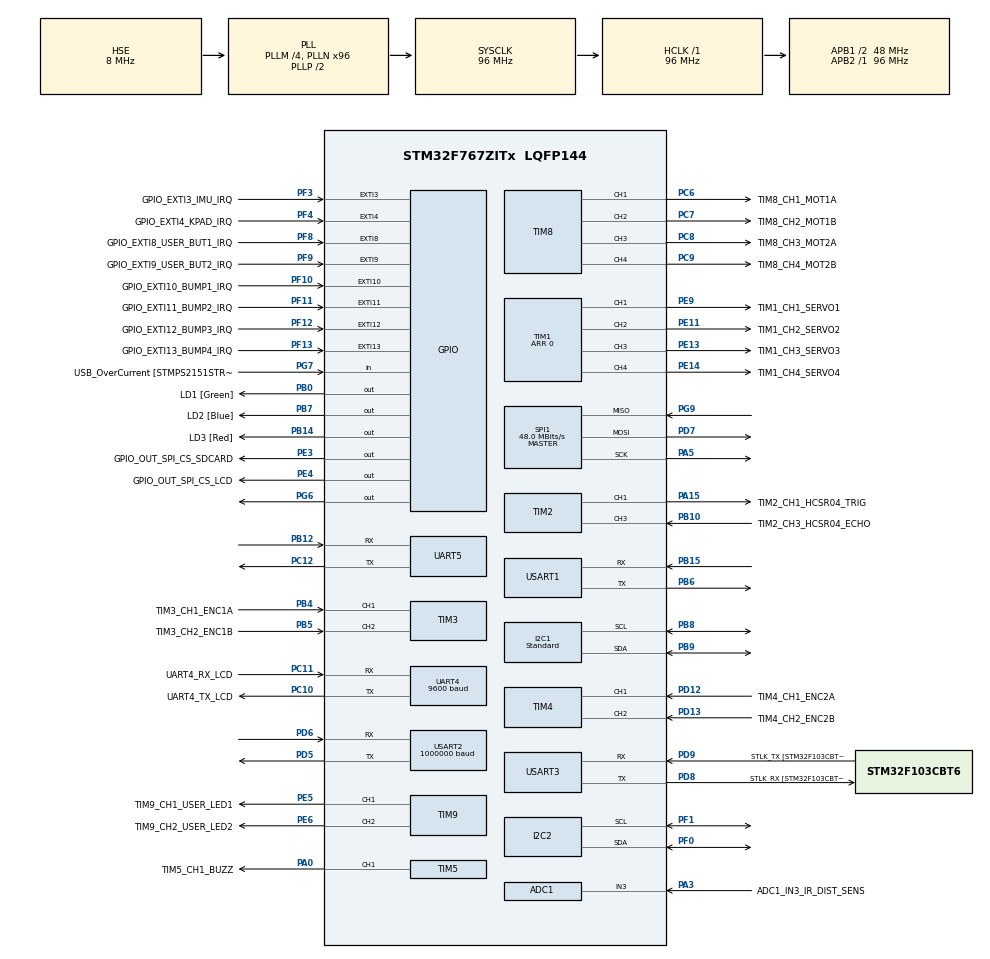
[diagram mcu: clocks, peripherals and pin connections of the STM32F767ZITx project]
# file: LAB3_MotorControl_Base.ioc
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ADC1.Channel-1\#ChannelRegularConversion=ADC_CHANNEL_3
ADC1.NbrOfConversionFlag=1
ADC1.Rank-1\#ChannelRegularConversion=1
ADC1.SamplingTime-1\#ChannelRegularConversion=ADC_SAMPLETIME_3CYCLES
ADC1.master=1
I2C1.I2C_Speed_Mode=I2C_Standard
I2C1.Timing=0x20303E5D
I2C2.Timing=0x20303E5D
Mcu.Family=STM32F7
Mcu.Name=STM32F767ZITx
Mcu.Package=LQFP144
Mcu.UserConstants=TIM3_ARR_VALUE,3839;TIM4_ARR_VALUE,3839;TIM8_PSC_VALUE,959;TIM8_ARR_VALUE,399;TIM6_PSC_VALUE,959;TIM6_ARR_VALUE,999;TIM1_PSC_VALUE,959;TIM1_ARR_VALUE,1999
NVIC.EXTI4_IRQn=true\:0\:0\:true\:false\:true\:true\:true\:true
NVIC.PriorityGroup=NVIC_PRIORITYGROUP_4
NVIC.TIM6_DAC_IRQn=true\:7\:0\:true\:false\:true\:true\:true\:true
PA0/WKUP.GPIO_Label=TIM5_CH1_BUZZ
PA0/WKUP.Signal=S_TIM5_CH1
PA1.GPIO_Label=RMII_REF_CLK [LAN8742A-CZ-TR_REFCLK0]
PA1.Signal=ETH_REF_CLK
PA10.GPIO_Label=USB_ID
PA10.Signal=USB_OTG_FS_ID
PA11.GPIO_Label=USB_DM
PA11.Signal=USB_OTG_FS_DM
PA12.GPIO_Label=USB_DP
PA12.Signal=USB_OTG_FS_DP
PA13.GPIO_Label=TMS
PA13.Mode=Serial_Wire
PA13.Signal=SYS_JTMS-SWDIO
PA14.GPIO_Label=TCK
PA14.Mode=Serial_Wire
PA14.Signal=SYS_JTCK-SWCLK
PA15.GPIO_Label=TIM2_CH1_HCSR04_TRIG
PA15.Signal=S_TIM2_CH1_ETR
PA2.GPIO_Label=RMII_MDIO [LAN8742A-CZ-TR_MDIO]
PA2.Signal=ETH_MDIO
PA3.GPIO_Label=ADC1_IN3_IR_DIST_SENS
PA3.Signal=ADCx_IN3
PA5.Mode=Full_Duplex_Master
PA5.Signal=SPI1_SCK
PA7.GPIO_Label=RMII_CRS_DV [LAN8742A-CZ-TR_CRS_DV]
PA7.Signal=ETH_CRS_DV
PA8.GPIO_Label=USB_SOF [TP1]
PA8.Signal=USB_OTG_FS_SOF
PA9.GPIO_Label=USB_VBUS
PA9.Signal=USB_OTG_FS_VBUS
PB0.GPIO_Label=LD1 [Green]
PB0.Signal=GPIO_Output
PB10.GPIO_Label=TIM2_CH3_HCSR04_ECHO
PB10.Signal=S_TIM2_CH3
PB12.Mode=Asynchronous
PB12.Signal=UART5_RX
PB13.GPIO_Label=RMII_TXD1 [LAN8742A-CZ-TR_TXD1]
PB13.Signal=ETH_TXD1
PB14.GPIO_Label=LD3 [Red]
PB14.Signal=GPIO_Output
PB15.Mode=Asynchronous
PB15.Signal=USART1_RX
PB3.GPIO_Label=SWO
PB3.Signal=SYS_JTDO-SWO
PB4.GPIO_Label=TIM3_CH1_ENC1A
PB4.Signal=S_TIM3_CH1
PB5.GPIO_Label=TIM3_CH2_ENC1B
PB5.Signal=S_TIM3_CH2
PB6.Mode=Asynchronous
PB6.Signal=USART1_TX
PB7.GPIO_Label=LD2 [Blue]
PB7.Signal=GPIO_Output
PB8.GPIO_Pu=GPIO_PULLUP
PB8.Mode=I2C
PB8.Signal=I2C1_SCL
PB9.GPIO_Pu=GPIO_PULLUP
PB9.Mode=I2C
PB9.Signal=I2C1_SDA
PC1.GPIO_Label=RMII_MDC [LAN8742A-CZ-TR_MDC]
PC1.Signal=ETH_MDC
PC10.GPIO_Label=UART4_TX_LCD
PC10.Mode=Asynchronous
PC10.Signal=UART4_TX
PC11.GPIO_Label=UART4_RX_LCD
PC11.Mode=Asynchronous
PC11.Signal=UART4_RX
PC12.Mode=Asynchronous
PC12.Signal=UART5_TX
PC14/OSC32_IN.Mode=LSE-External-Oscillator
PC14/OSC32_IN.Signal=RCC_OSC32_IN
PC15/OSC32_OUT.Mode=LSE-External-Oscillator
PC15/OSC32_OUT.Signal=RCC_OSC32_OUT
PC4.GPIO_Label=RMII_RXD0 [LAN8742A-CZ-TR_RXD0]
PC4.Signal=ETH_RXD0
PC5.GPIO_Label=RMII_RXD1 [LAN8742A-CZ-TR_RXD1]
PC5.Signal=ETH_RXD1
PC6.GPIO_Label=TIM8_CH1_MOT1A
PC6.Signal=S_TIM8_CH1
PC7.GPIO_Label=TIM8_CH2_MOT1B
PC7.Signal=S_TIM8_CH2
PC8.GPIO_Label=TIM8_CH3_MOT2A
PC8.Signal=S_TIM8_CH3
PC9.GPIO_Label=TIM8_CH4_MOT2B
PC9.Signal=S_TIM8_CH4
PD12.GPIO_Label=TIM4_CH1_ENC2A
PD12.Signal=S_TIM4_CH1
PD13.GPIO_Label=TIM4_CH2_ENC2B
PD13.Signal=S_TIM4_CH2
PD5.Mode=Asynchronous
PD5.Signal=USART2_TX
PD6.Mode=Asynchronous
PD6.Signal=USART2_RX
PD7.Mode=Full_Duplex_Master
PD7.Signal=SPI1_MOSI
PD8.GPIO_Label=STLK_RX [STM32F103CBT6_PA3]
PD8.Mode=Asynchronous
PD8.Signal=USART3_TX
PD9.GPIO_Label=STLK_TX [STM32F103CBT6_PA2]
PD9.Mode=Asynchronous
PD9.Signal=USART3_RX
PE11.GPIO_Label=TIM1_CH2_SERVO2
PE11.Signal=S_TIM1_CH2
PE13.GPIO_Label=TIM1_CH3_SERVO3
PE13.Signal=S_TIM1_CH3
PE14.GPIO_Label=TIM1_CH4_SERVO4
PE14.Signal=S_TIM1_CH4
PE3.GPIO_Label=GPIO_OUT_SPI_CS_SDCARD
PE3.Signal=GPIO_Output
PE4.GPIO_Label=GPIO_OUT_SPI_CS_LCD
PE4.Signal=GPIO_Output
PE5.GPIO_Label=TIM9_CH1_USER_LED1
PE5.Signal=S_TIM9_CH1
PE6.GPIO_Label=TIM9_CH2_USER_LED2
PE6.Signal=S_TIM9_CH2
PE9.GPIO_Label=TIM1_CH1_SERVO1
PE9.Signal=S_TIM1_CH1
PF0.GPIO_Pu=GPIO_PULLUP
PF0.Mode=I2C
PF0.Signal=I2C2_SDA
PF1.GPIO_Pu=GPIO_PULLUP
PF1.Mode=I2C
PF1.Signal=I2C2_SCL
PF10.GPIO_Label=GPIO_EXTI10_BUMP1_IRQ
PF10.Signal=GPXTI10
PF11.GPIO_Label=GPIO_EXTI11_BUMP2_IRQ
PF11.Signal=GPXTI11
PF12.GPIO_Label=GPIO_EXTI12_BUMP3_IRQ
PF12.Signal=GPXTI12
PF13.GPIO_Label=GPIO_EXTI13_BUMP4_IRQ
PF13.Signal=GPXTI13
PF3.GPIO_Label=GPIO_EXTI3_IMU_IRQ
PF3.Signal=GPXTI3
PF4.GPIO_Label=GPIO_EXTI4_KPAD_IRQ
PF4.GPIO_ModeDefaultEXTI=GPIO_MODE_IT_FALLING
PF4.Signal=GPXTI4
PF8.GPIO_Label=GPIO_EXTI8_USER_BUT1_IRQ
PF8.Signal=GPXTI8
PF9.GPIO_Label=GPIO_EXTI9_USER_BUT2_IRQ
PF9.Signal=GPXTI9
PG11.GPIO_Label=RMII_TX_EN [LAN8742A-CZ-TR_TXEN]
PG11.Signal=ETH_TX_EN
PG13.GPIO_Label=RMII_TXD0 [LAN8742A-CZ-TR_TXD0]
PG13.Signal=ETH_TXD0
PG6.Signal=GPIO_Output
PG7.GPIO_Label=USB_OverCurrent [STMPS2151STR_FAULT]
PG7.Signal=GPIO_Input
PG9.Mode=Full_Duplex_Master
PG9.Signal=SPI1_MISO
PH0/OSC_IN.GPIO_Label=MCO [STM32F103CBT6_PA8]
PH0/OSC_IN.Mode=HSE-External-Clock-Source
PH0/OSC_IN.Signal=RCC_OSC_IN
PH1/OSC_OUT.Mode=HSE-External-Clock-Source
PH1/OSC_OUT.Signal=RCC_OSC_OUT
ProjectManager.HeapSize=0x200
ProjectManager.StackSize=0x400
ProjectManager.TargetToolchain=STM32CubeIDE
RCC.48MHZClocksFreq_Value=24000000
RCC.AHBFreq_Value=96000000
RCC.APB1CLKDivider=RCC_HCLK_DIV2
RCC.APB1Freq_Value=48000000
RCC.APB1TimFreq_Value=96000000
RCC.APB2Freq_Value=96000000
RCC.APB2TimFreq_Value=96000000
RCC.CortexFreq_Value=96000000
RCC.HCLKFreq_Value=96000000
RCC.HSE_VALUE=8000000
RCC.HSI_VALUE=16000000
RCC.PLLM=4
RCC.PLLMUL=RCC_PLL_MUL9
RCC.PLLN=96
RCC.PLLQ=4
RCC.PLLSourceVirtual=RCC_PLLSOURCE_HSE
RCC.PRESCALERUSB=RCC_USBCLKSOURCE_PLL_DIV1_5
RCC.SYSCLKFreq_VALUE=96000000
RCC.SYSCLKSource=RCC_SYSCLKSOURCE_PLLCLK
RCC.SYSCLKSourceVirtual=RCC_SYSCLKSOURCE_PLLCLK
RCC.USBFreq_Value=48000000
RCC.VCOOutputFreq_Value=192000000
SH.ADCx_IN3.0=ADC1_IN3,IN3
SH.S_TIM1_CH1.0=TIM1_CH1,Forced Output1 CH1
SH.S_TIM1_CH2.0=TIM1_CH2,Forced Output2 CH2
SH.S_TIM1_CH3.0=TIM1_CH3,Forced Output3 CH3
SH.S_TIM1_CH4.0=TIM1_CH4,Forced Output4 CH4
SH.S_TIM2_CH1_ETR.0=TIM2_CH1,PWM Generation1 CH1
SH.S_TIM2_CH3.0=TIM2_CH3,Input_Capture3_from_TI3
SH.S_TIM3_CH1.0=TIM3_CH1,Encoder_Interface
SH.S_TIM3_CH2.0=TIM3_CH2,Encoder_Interface
SH.S_TIM4_CH1.0=TIM4_CH1,Encoder_Interface
SH.S_TIM4_CH2.0=TIM4_CH2,Encoder_Interface
SH.S_TIM5_CH1.0=TIM5_CH1,PWM Generation1 CH1
SH.S_TIM8_CH1.0=TIM8_CH1,PWM Generation1 CH1
SH.S_TIM8_CH2.0=TIM8_CH2,PWM Generation2 CH2
SH.S_TIM8_CH3.0=TIM8_CH3,PWM Generation3 CH3
SH.S_TIM8_CH4.0=TIM8_CH4,PWM Generation4 CH4
SH.S_TIM9_CH1.0=TIM9_CH1,PWM Generation1 CH1
SH.S_TIM9_CH2.0=TIM9_CH2,PWM Generation2 CH2
SPI1.CalculateBaudRate=48.0 MBits/s
SPI1.Direction=SPI_DIRECTION_2LINES
SPI1.Mode=SPI_MODE_MASTER
SPI1.VirtualType=VM_MASTER
TIM1.Channel-Forced\ Output1\ CH1=TIM_CHANNEL_1
TIM1.Channel-Forced\ Output2\ CH2=TIM_CHANNEL_2
TIM1.Channel-Forced\ Output3\ CH3=TIM_CHANNEL_3
TIM1.Channel-Forced\ Output4\ CH4=TIM_CHANNEL_4
TIM1.OCPolarity_1=TIM_OCPOLARITY_LOW
TIM1.OCPolarity_2=TIM_OCPOLARITY_LOW
TIM1.OCPolarity_3=TIM_OCPOLARITY_LOW
TIM1.OCPolarity_4=TIM_OCPOLARITY_LOW
TIM1.Period=0
TIM2.Channel-Input_Capture3_from_TI3=TIM_CHANNEL_3
TIM2.Channel-PWM\ Generation1\ CH1=TIM_CHANNEL_1
TIM3.EncoderMode=TIM_ENCODERMODE_TI12
TIM3.IC1Filter=15
TIM3.IC2Filter=15
TIM3.Period=TIM3_ARR_VALUE
TIM4.EncoderMode=TIM_ENCODERMODE_TI12
TIM4.IC1Filter=15
TIM4.IC2Filter=15
TIM4.Period=TIM4_ARR_VALUE
TIM5.Channel-PWM\ Generation1\ CH1=TIM_CHANNEL_1
TIM6.Period=TIM6_ARR_VALUE
TIM6.Prescaler=TIM6_PSC_VALUE
TIM8.Channel-PWM\ Generation1\ CH1=TIM_CHANNEL_1
TIM8.Channel-PWM\ Generation2\ CH2=TIM_CHANNEL_2
TIM8.Channel-PWM\ Generation3\ CH3=TIM_CHANNEL_3
TIM8.Channel-PWM\ Generation4\ CH4=TIM_CHANNEL_4
TIM8.Period=TIM8_ARR_VALUE
TIM8.Prescaler=TIM8_PSC_VALUE
TIM9.Channel-PWM\ Generation1\ CH1=TIM_CHANNEL_1
TIM9.Channel-PWM\ Generation2\ CH2=TIM_CHANNEL_2
UART4.BaudRate=9600
USART1.VirtualMode-Asynchronous=VM_ASYNC
USART2.BaudRate=1000000
USART2.VirtualMode-Asynchronous=VM_ASYNC
USART3.VirtualMode-Asynchronous=VM_ASYNC
VP_TIM1_VS_ClockSourceINT.Mode=Internal
VP_TIM2_VS_ClockSourceINT.Mode=Internal
VP_TIM5_VS_ClockSourceINT.Mode=Internal
VP_TIM6_VS_ClockSourceINT.Mode=Enable_Timer
VP_TIM8_VS_ClockSourceINT.Mode=Internal
board=NUCLEO-F767ZI

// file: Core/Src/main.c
/* USER CODE BEGIN Header */
/**
  ******************************************************************************
  * @file           : main.c
  * @brief          : Main program body
  ******************************************************************************
  * @attention
  *
  * <h2><center>&copy; Copyright (c) 2021 STMicroelectronics.
  * All rights reserved.</center></h2>
  *
  * This software component is licensed by ST under BSD 3-Clause license,
  * the "License"; You may not use this file except in compliance with the
  * License. You may obtain a copy of the License at:
  *                        opensource.org/licenses/BSD-3-Clause
  *
  ******************************************************************************
  */
/* USER CODE END Header */
#include "main.h"

/* USER CODE BEGIN Includes */
#include <math.h>
#include <stdbool.h>
#include "ertc-datalogger.h"
#include <stdio.h>
#include <string.h>
#include "SX1509_Registers.h"
/* USER CODE END Includes */

/* USER CODE BEGIN PD */
//#define HAL_TIMEOUT 1

#define I2C_TIMEOUT 200

#define SX1509_I2C_ADDR1 0x3E //	SX1509 Proxy Sensors I2C address
#define SX1509_I2C_ADDR2 0x3F //	SX1509 Keypad I2C address

#define TIM3_ARR_VALUE 3840 // assuming we are using 4X encoder mode
#define TIM4_ARR_VALUE 3840

#define TS	0.01

#define Kp 2 //0.14 * 1/RPM2RADS
#define Ki 30 //2.14 * 1/RPM2RADS
#define Ts5 0.21 //settling time [s]
#define Kw 30//5/Ts5

#define V 2*M_PI/3840 /*how much radiant is in encoder step*/

#define VBATT	8.0
#define V2DUTY	((float)(TIM8_ARR_VALUE+1)/VBATT)
#define DUTY2V	((float)VBATT/(TIM8_ARR_VALUE+1))

#define RPM2RADS	2*M_PI/60
/* USER CODE END PD */

ADC_HandleTypeDef hadc1;

I2C_HandleTypeDef hi2c1;
I2C_HandleTypeDef hi2c2;

SPI_HandleTypeDef hspi1;

TIM_HandleTypeDef htim1;
TIM_HandleTypeDef htim2;
TIM_HandleTypeDef htim3;
TIM_HandleTypeDef htim4;
TIM_HandleTypeDef htim5;
TIM_HandleTypeDef htim6;
TIM_HandleTypeDef htim8;
TIM_HandleTypeDef htim9;

UART_HandleTypeDef huart4;
UART_HandleTypeDef huart5;
UART_HandleTypeDef huart1;
UART_HandleTypeDef huart2;
UART_HandleTypeDef huart3;

/* USER CODE BEGIN PV */
struct ertc_dlog logger;
/* USER CODE END PV */

void SystemClock_Config(void);
static void MX_GPIO_Init(void);
static void MX_USART3_UART_Init(void);
static void MX_ADC1_Init(void);
static void MX_I2C1_Init(void);
static void MX_I2C2_Init(void);
static void MX_SPI1_Init(void);
static void MX_TIM1_Init(void);
static void MX_TIM2_Init(void);
static void MX_TIM3_Init(void);
static void MX_TIM4_Init(void);
static void MX_TIM5_Init(void);
static void MX_TIM8_Init(void);
static void MX_UART4_Init(void);
static void MX_UART5_Init(void);
static void MX_USART1_UART_Init(void);
static void MX_USART2_UART_Init(void);
static void MX_TIM9_Init(void);
static void MX_TIM6_Init(void);

/* USER CODE BEGIN 0 */

char keyinput[5];
int i=0;
uint8_t regCol, regRow;
int8_t negativeFlag = 1;

struct datalog {
	float speed1,speed2;
	float motor1,motor2;
	int getIn;
} data;

int temp = 0;

float target = 0; //[rad/s]

 // KeyPad Input management
const char keypadLayout[4][4] = {
    {'*', '0', '#', 'D'},
    {'7', '8', '9', 'C'},
    {'4', '5', '6', 'B'},
    {'1', '2', '3', 'A'}};

int ve_char2var_int(char vector[])
{
	int variable=0; //output

    sscanf(vector, "%d", &variable);

	return variable;
}

float saturation(float value, float min, float max)
{
	if (value > max)
		value=max;
	else if (value < min)
		value=min;
	return value;
}

/*motor1*/
float PI1 (float error){
	float prop = Kp* error;
	static float I1 ;
	I1 = I1 + (TS * Ki * error);

	// ANTIWIND-UP
/*
	float toReturn = prop+I1;
	float sat = toReturn - saturation(toReturn, -7.9, 7.9);
	I1 -= sat * Kw * TS;
*/

	return saturation((prop + I1), -7.9, 7.9);
}

/*motor2*/
float PI2 (float error){
	float prop = Kp* error;
	static float I2 ;
	I2 = I2 + (TS * Ki * error);

	// ANTIWIND-UP
/*
	float toReturn = prop+I2;
	float sat = toReturn - saturation((prop + I2), -7.9, 7.9);
	I2 -= sat * Kw * TS;
*/

	return saturation((prop + I2), -7.9, 7.9);
}

int32_t encoder1(void){

	uint32_t TIM3_CurrentCount;
	int32_t TIM3_DiffCount;
	static uint32_t TIM3_PreviousCount = 0;
	TIM3_CurrentCount = __HAL_TIM_GET_COUNTER(&htim3);

	/* evaluate increment of TIM3 counter from previous count */
	if (__HAL_TIM_IS_TIM_COUNTING_DOWN(&htim3))
	{
		/* check for counter underflow */
		if (TIM3_CurrentCount <= TIM3_PreviousCount)
			TIM3_DiffCount = TIM3_CurrentCount - TIM3_PreviousCount;
		else
			TIM3_DiffCount = -((TIM3_ARR_VALUE+1) - TIM3_CurrentCount) - TIM3_PreviousCount;
	}
	else
	{
		/* check for counter overflow */
		if (TIM3_CurrentCount >= TIM3_PreviousCount)
			TIM3_DiffCount = TIM3_CurrentCount - TIM3_PreviousCount;
		else
			TIM3_DiffCount = ((TIM3_ARR_VALUE+1) - TIM3_PreviousCount) + TIM3_CurrentCount;
	}

	/*update of previous count*/
	TIM3_PreviousCount = TIM3_CurrentCount;

	return TIM3_DiffCount;

}

int32_t encoder2(void){

	uint32_t TIM4_CurrentCount;
	int32_t TIM4_DiffCount;
	static uint32_t TIM4_PreviousCount = 0;
	TIM4_CurrentCount = __HAL_TIM_GET_COUNTER(&htim4);

	/* evaluate increment of TIM4 counter from previous count */
	if (__HAL_TIM_IS_TIM_COUNTING_DOWN(&htim4))
	{
		/* check for counter underflow */
		if (TIM4_CurrentCount <= TIM4_PreviousCount)
			TIM4_DiffCount = TIM4_CurrentCount - TIM4_PreviousCount;
		else
			TIM4_DiffCount = -((TIM4_ARR_VALUE+1) - TIM4_CurrentCount) - TIM4_PreviousCount;
	}
	else
	{
		/* check for counter overflow */
		if (TIM4_CurrentCount >= TIM4_PreviousCount)
			TIM4_DiffCount = TIM4_CurrentCount - TIM4_PreviousCount;
		else
			TIM4_DiffCount = ((TIM4_ARR_VALUE+1) - TIM4_PreviousCount) + TIM4_CurrentCount;
	}

	/*update of previous count*/
	TIM4_PreviousCount = TIM4_CurrentCount;

	return TIM4_DiffCount;

}

void motor1_PWM (int32_t duty)
{
	if (duty >= 0) { // rotate forward

		/* alternate between forward and brake, TIM8_ARR_VALUE is a define */
		 __HAL_TIM_SET_COMPARE(&htim8, TIM_CHANNEL_1, (uint32_t)TIM8_ARR_VALUE); /*max*/
		 __HAL_TIM_SET_COMPARE(&htim8, TIM_CHANNEL_2, TIM8_ARR_VALUE - duty);

		/* alternate between forward and coast */
	/*	 __HAL_TIM_SET_COMPARE(&htim8, TIM_CHANNEL_1, (uint32_t)duty);
		 __HAL_TIM_SET_COMPARE(&htim8, TIM_CHANNEL_2, 0);
*/
	} else { // rotate backward

		/* alternate between forward and brake, TIM8_ARR_VALUE is a define */
		__HAL_TIM_SET_COMPARE(&htim8, TIM_CHANNEL_1,  TIM8_ARR_VALUE + duty);
		__HAL_TIM_SET_COMPARE(&htim8, TIM_CHANNEL_2, (uint32_t)TIM8_ARR_VALUE);

		/* alternate between forward and coast */
		/* __HAL_TIM_SET_COMPARE(&htim8, TIM_CHANNEL_1, 0);
		 __HAL_TIM_SET_COMPARE(&htim8, TIM_CHANNEL_2, - (uint32_t)duty);
	*/}
}

void motor2_PWM (int32_t duty)
{
	if (duty >= 0) { // rotate forward

		/*alternate between forward and brake, TIM8_ARR_VALUE is a define */
		__HAL_TIM_SET_COMPARE(&htim8, TIM_CHANNEL_3, (uint32_t)TIM8_ARR_VALUE); /*max*/
		__HAL_TIM_SET_COMPARE(&htim8, TIM_CHANNEL_4, TIM8_ARR_VALUE - duty);

		/* alternate between forward and coast */
		/* __HAL_TIM_SET_COMPARE(&htim8, TIM_CHANNEL_3, (uint32_t)duty);
		 __HAL_TIM_SET_COMPARE(&htim8, TIM_CHANNEL_4, 0);
*/
	} else { // rotate backward

		/* alternate between forward and brake, TIM8_ARR_VALUE is a define */
		__HAL_TIM_SET_COMPARE(&htim8, TIM_CHANNEL_3,  TIM8_ARR_VALUE + duty);
		__HAL_TIM_SET_COMPARE(&htim8, TIM_CHANNEL_4, (uint32_t)TIM8_ARR_VALUE);

		/* alternate between forward and coast */
		/* __HAL_TIM_SET_COMPARE(&htim8, TIM_CHANNEL_3, 0);
		 __HAL_TIM_SET_COMPARE(&htim8, TIM_CHANNEL_4, - (uint32_t)duty);
	*/}
}

void HAL_TIM_PeriodElapsedCallback(TIM_HandleTypeDef *htim)
{
	/* Speed ctrl routine */
	if(htim->Instance == TIM6)
	{
		int32_t ENC1_DiffCount = encoder1();
		int32_t ENC2_DiffCount = encoder2();

		float speed1 = ENC1_DiffCount * V *1/TS ; // [rad/s]
		float speed2 = ENC2_DiffCount * V *1/TS ; // [rad/s]

		float error1 = target-speed1;
		float error2 = target-speed2;

		float contAct1 = PI1(error1);
		float contAct2 = PI2(error2);

		motor1_PWM (contAct1*V2DUTY);
		motor2_PWM (contAct2*V2DUTY);

     	/*	Prepare data packet */
		data.speed1 = speed1;
		data.speed2 = speed2;
		data.motor1 = contAct1;
		data.motor2 = contAct2;
		data.getIn  = temp;
		ertc_dlog_send(&logger, &data, sizeof(data));
	}
}

// Routine for external interrupt....
// TODO: Remains to set everything related to I2C...
//

void HAL_GPIO_EXTI_Callback(uint16_t GPIO_Pin)
{

  //printf("Interrupt on pin (%d).\n", GPIO_Pin);

	data.speed1 = 0;
	data.speed2 = 0;
	data.motor1 = 0;
	data.motor2 = 0;
	data.getIn  = GPIO_Pin;
	ertc_dlog_send(&logger, &data, sizeof(data));

  // your code here
  if (GPIO_Pin==16){
	 HAL_StatusTypeDef status1, status2;
	 status1 = HAL_I2C_Mem_Read(&hi2c1, SX1509_I2C_ADDR2 << 1, REG_KEY_DATA_1, 1, &regCol, 1, I2C_TIMEOUT);
	 status2 = HAL_I2C_Mem_Read(&hi2c1, SX1509_I2C_ADDR2 << 1, REG_KEY_DATA_2, 1, &regRow, 1, I2C_TIMEOUT);
	 //printf("I2C communication error (%X).\n", status2);
	 //printf("I2C communication error (%X).\n", status1);

	 switch (regRow){
		 case 254:
			 regRow=0;
			 break;
		 case 253:
			 regRow=1;
			 break;
		 case 251:
			 regRow=2;
			 break;
		 case 247:
			 regRow=3;
			 break;
		 default:
			 //printf("error row \n");
			 break;
	 }

	 switch (regCol){
		 case 254:
			 regCol=0;
			 break;
		 case 253:
			 regCol=1;
			 break;
		 case 251:
			 regCol=2;
			 break;
		 case 247:
			 regCol=3;
			 break;
		 default:
			 //printf("error column \n");
			 break;
	 }

	 //printf("Row: %d \n", regRow);
	 //printf("Column: %d \n", regCol);
	 //printf("Keypad button: %c \n", keypadLayout[regRow][regCol]);

	 if(keypadLayout[regRow][regCol]== '*') // Check if press *, if so, the number insered is negative.
		 negativeFlag*=-1;
	 else if(keypadLayout[regRow][regCol]!='#')//check if press # and if not mem the value
	 {
		 keyinput[i]= keypadLayout[regRow][regCol];
		 i=(i+1)%4; //Index update and check whether Index exceeds the bounds (i.e. i>=4);
	 }
	 else
	 {
		 if (i!=0)
			 keyinput[i]='\0';
		 else
			 keyinput[4]='\0';
		 i=0;
		 target = negativeFlag*ve_char2var_int(keyinput);
		 negativeFlag=1;
	 }
  }
}

/* USER CODE END 0 */

int main(void)
{
  /* USER CODE BEGIN 1 */
	uint8_t data;
	HAL_StatusTypeDef status;
  /* USER CODE END 1 */

  /* MCU Configuration--------------------------------------------------------*/

  /* Reset of all peripherals, Initializes the Flash interface and the Systick. */
  HAL_Init();

  /* Configure the system clock */
  SystemClock_Config();

  /* Initialize all configured peripherals */
  MX_GPIO_Init();
  MX_USART3_UART_Init();
  MX_ADC1_Init();
  MX_I2C1_Init();
  MX_I2C2_Init();
  MX_SPI1_Init();
  MX_TIM1_Init();
  MX_TIM2_Init();
  MX_TIM3_Init();
  MX_TIM4_Init();
  MX_TIM5_Init();
  MX_TIM8_Init();
  MX_UART4_Init();
  MX_UART5_Init();
  MX_USART1_UART_Init();
  MX_USART2_UART_Init();
  MX_TIM9_Init();
  MX_TIM6_Init();
  /* USER CODE BEGIN 2 */

  logger.uart_handle = huart3; // for serial
  //logger.uart_handle = huart2; // for wifi

  /* Reset LCD */
  HAL_GPIO_WritePin(GPIO_OUT_SPI_CS_LCD_GPIO_Port, GPIO_OUT_SPI_CS_LCD_Pin, GPIO_PIN_SET);

  //disable EXTI4_IRQ during SX1509 initialization
  HAL_NVIC_DisableIRQ(EXTI4_IRQn);

  /* Software reset */
    data = 0x12;
    status = HAL_I2C_Mem_Write(&hi2c1, SX1509_I2C_ADDR2 << 1, REG_RESET, 1, &data, 1, I2C_TIMEOUT);
    //if (status != HAL_OK)
      //printf("I2C communication error (%X).\n", status);

    data = 0x34;
    status = HAL_I2C_Mem_Write(&hi2c1, SX1509_I2C_ADDR2 << 1, REG_RESET, 1, &data, 1, I2C_TIMEOUT);
    //if (status != HAL_OK)
      //printf("I2C communication error (%X).\n", status);

    HAL_Delay(100);

    /* Set KeyPad scanning engine */

    /* Set RegClock to 0x40 (enable internal oscillator; 2MHz freq) */
    data = 0x40;
    status = HAL_I2C_Mem_Write(&hi2c1, SX1509_I2C_ADDR2 << 1, REG_CLOCK, 1, &data, 1, I2C_TIMEOUT);
    //if (status != HAL_OK)
      //printf("I2C communication error (%X).\n", status);

    /* Set Bank A RegDir to 0xF0 (IO[0:3] as out) */
    data = 0xF0;
    status = HAL_I2C_Mem_Write(&hi2c1, SX1509_I2C_ADDR2 << 1, REG_DIR_A, 1, &data, 1, I2C_TIMEOUT);
    //if (status != HAL_OK)
      //printf("I2C communication error (%X).\n", status);

    /* Set Bank B RegDir to 0x0F (IO[8:11] as in) */
    data = 0x0F;
    status = HAL_I2C_Mem_Write(&hi2c1, SX1509_I2C_ADDR2 << 1, REG_DIR_B, 1, &data, 1, I2C_TIMEOUT);
    //if (status != HAL_OK)
      //printf("I2C communication error (%X).\n", status);

    /* Set Bank A RegOpenDrain to 0x0F (IO[0:3] as open-drain outputs) */
    data = 0x0F;
    status = HAL_I2C_Mem_Write(&hi2c1, SX1509_I2C_ADDR2 << 1, REG_OPEN_DRAIN_A, 1, &data, 1, I2C_TIMEOUT);
    //if (status != HAL_OK)
      //printf("I2C communication error (%X).\n", status);

    /* Set Bank B RegPullup to 0x0F (pull-ups enabled on inputs IO[8:11]) */
    data = 0x0F;
    status = HAL_I2C_Mem_Write(&hi2c1, SX1509_I2C_ADDR2 << 1, REG_PULL_UP_B, 1, &data, 1, I2C_TIMEOUT);
    //if (status != HAL_OK)
      //printf("I2C communication error (%X).\n", status);

    /* Set Bank B RegDebounceEnable to 0x0F (enable debouncing on IO[8:11]) */
    data = 0x0F;
    status = HAL_I2C_Mem_Write(&hi2c1, SX1509_I2C_ADDR2 << 1, REG_DEBOUNCE_ENABLE_B, 1, &data, 1, I2C_TIMEOUT);
    //if (status != HAL_OK)
      //printf("I2C communication error (%X).\n", status);

    /* Set RegDebounceConfig to 0x05 (16ms debounce time) */
    data = 0x05;
    status = HAL_I2C_Mem_Write(&hi2c1, SX1509_I2C_ADDR2 << 1, REG_DEBOUNCE_CONFIG, 1, &data, 1, I2C_TIMEOUT);
    //if (status != HAL_OK)
      //printf("I2C communication error (%X).\n", status);

    /* Set RegKeyConfig1 to 0x7D (8s auto-sleep; 32ms scan time per row) */
    data = 0x7D;
    status = HAL_I2C_Mem_Write(&hi2c1, SX1509_I2C_ADDR2 << 1, REG_KEY_CONFIG_1, 1, &data, 1, I2C_TIMEOUT);
    //if (status != HAL_OK)
      //printf("I2C communication error (%X).\n", status);

    /* Set RegKeyConfig2 to 0x1B (4 rows; 4 columns) */
    data = 0x1B;
    status = HAL_I2C_Mem_Write(&hi2c1, SX1509_I2C_ADDR2 << 1, REG_KEY_CONFIG_2, 1, &data, 1, I2C_TIMEOUT);
    //if (status != HAL_OK)
      //printf("I2C communication error (%X).\n", status);

    /* Enable EXTI4_IRQ after SX1509 initialization */
    HAL_Delay(100);
    HAL_NVIC_EnableIRQ(EXTI4_IRQn);

    /* Disable EXTI2_IRQ during SX1509 initialization */
    HAL_NVIC_DisableIRQ(EXTI2_IRQn);

    /* Software reset */
    data = 0x12;
    status = HAL_I2C_Mem_Write(&hi2c1, SX1509_I2C_ADDR1 << 1, REG_RESET, 1, &data, 1, I2C_TIMEOUT);
    //if (status != HAL_OK)
      //printf("I2C communication error (%X).\n", status);

    data = 0x34;
    status = HAL_I2C_Mem_Write(&hi2c1, SX1509_I2C_ADDR1 << 1, REG_RESET, 1, &data, 1, I2C_TIMEOUT);
    //if (status != HAL_OK)
      //printf("I2C communication error (%X).\n", status);

    HAL_Delay(100);

    /* Set RegDirA to 0xFF (all IO of Bank A configured as inputs) */
    data = 0xFF; // 0 = out; 1 = in
    status = HAL_I2C_Mem_Write(&hi2c1, SX1509_I2C_ADDR1 << 1, REG_DIR_A, 1, &data, 1, I2C_TIMEOUT);
    //if (status != HAL_OK)
      //printf("I2C communication error (%X).\n", status);

    /* Set RegDirB to 0xFF (all IO of Bank B configured as inputs) */
    data = 0xFF; // 0 = out; 1 = in
    status = HAL_I2C_Mem_Write(&hi2c1, SX1509_I2C_ADDR1 << 1, REG_DIR_B, 1, &data, 1, I2C_TIMEOUT);
    //if (status != HAL_OK)
      //printf("I2C communication error (%X).\n", status);

    /* Set RegInterruptMaskA to 0x00 (all IO of Bank A will trigger an interrupt) */
    data = 0x00;
    status = HAL_I2C_Mem_Write(&hi2c1, SX1509_I2C_ADDR1 << 1, REG_INTERRUPT_MASK_A, 1, &data, 1, I2C_TIMEOUT);
    //if (status != HAL_OK)
      //printf("I2C communication error (%X).\n", status);

    /* Set RegSenseHighA to 0xAA (IO[7:4] of Bank A will trigger an interrupt on falling edge) */
    data = 0xAA;
    status = HAL_I2C_Mem_Write(&hi2c1, SX1509_I2C_ADDR1 << 1, REG_SENSE_HIGH_A, 1, &data, 1, I2C_TIMEOUT);
    //if (status != HAL_OK)
      //printf("I2C communication error (%X).\n", status);

    /* Set RegSenseLowA to 0xAA (IO[3:0] of Bank A will trigger an interrupt on falling edge) */
    data = 0xAA;
    status = HAL_I2C_Mem_Write(&hi2c1, SX1509_I2C_ADDR1 << 1, REG_SENSE_LOW_A, 1, &data, 1, I2C_TIMEOUT);
    //if (status != HAL_OK)
      //printf("I2C communication error (%X).\n", status);

    /* Enable EXTI2_IRQ after SX1509 initialization */
    HAL_Delay(100);
    HAL_NVIC_EnableIRQ(EXTI2_IRQn);

  HAL_Delay(1000);

  /* Start encoders timers */
  HAL_TIM_Encoder_Start(&htim3, TIM_CHANNEL_ALL);
  HAL_TIM_Encoder_Start(&htim4, TIM_CHANNEL_ALL);

  /* Start servomotors PWM (avoid floating inputs to servomotors) */
  HAL_TIM_PWM_Start(&htim1, TIM_CHANNEL_1);
  HAL_TIM_PWM_Start(&htim1, TIM_CHANNEL_2);
  HAL_TIM_PWM_Start(&htim1, TIM_CHANNEL_3);
  HAL_TIM_PWM_Start(&htim1, TIM_CHANNEL_4);

  /* Start motor PWM */
  __HAL_TIM_SET_COMPARE(&htim8, TIM_CHANNEL_1, 0);
  __HAL_TIM_SET_COMPARE(&htim8, TIM_CHANNEL_2, 0);
  __HAL_TIM_SET_COMPARE(&htim8, TIM_CHANNEL_3, 0);
  __HAL_TIM_SET_COMPARE(&htim8, TIM_CHANNEL_4, 0);

  HAL_TIM_PWM_Start(&htim8, TIM_CHANNEL_1);
  HAL_TIM_PWM_Start(&htim8, TIM_CHANNEL_2);
  HAL_TIM_PWM_Start(&htim8, TIM_CHANNEL_3);
  HAL_TIM_PWM_Start(&htim8, TIM_CHANNEL_4);

  /* Start speed ctrl ISR */
  HAL_TIM_Base_Start_IT(&htim6);

  HAL_Delay(5000);
  target=-10; //[rad/s]

  /* USER CODE END 2 */

  /* Infinite loop */
  while (1)
  {

    /* USER CODE BEGIN 3 */
	  ertc_dlog_update(&logger);

  }
  /* USER CODE END 3 */
}

void SystemClock_Config(void)
{
  RCC_OscInitTypeDef RCC_OscInitStruct = {0};
  RCC_ClkInitTypeDef RCC_ClkInitStruct = {0};

  /** Configure LSE Drive Capability
  */
  HAL_PWR_EnableBkUpAccess();

  /** Configure the main internal regulator output voltage
  */
  __HAL_RCC_PWR_CLK_ENABLE();
  __HAL_PWR_VOLTAGESCALING_CONFIG(PWR_REGULATOR_VOLTAGE_SCALE3);

  /** Initializes the RCC Oscillators according to the specified parameters
  * in the RCC_OscInitTypeDef structure.
  */
  RCC_OscInitStruct.OscillatorType = RCC_OSCILLATORTYPE_HSE;
  RCC_OscInitStruct.HSEState = RCC_HSE_BYPASS;
  RCC_OscInitStruct.PLL.PLLState = RCC_PLL_ON;
  RCC_OscInitStruct.PLL.PLLSource = RCC_PLLSOURCE_HSE;
  RCC_OscInitStruct.PLL.PLLM = 4;
  RCC_OscInitStruct.PLL.PLLN = 96;
  RCC_OscInitStruct.PLL.PLLP = RCC_PLLP_DIV2;
  RCC_OscInitStruct.PLL.PLLQ = 4;
  RCC_OscInitStruct.PLL.PLLR = 2;
  if (HAL_RCC_OscConfig(&RCC_OscInitStruct) != HAL_OK)
  {
    Error_Handler();
  }

  /** Activate the Over-Drive mode
  */
  if (HAL_PWREx_EnableOverDrive() != HAL_OK)
  {
    Error_Handler();
  }

  /** Initializes the CPU, AHB and APB buses clocks
  */
  RCC_ClkInitStruct.ClockType = RCC_CLOCKTYPE_HCLK|RCC_CLOCKTYPE_SYSCLK
                              |RCC_CLOCKTYPE_PCLK1|RCC_CLOCKTYPE_PCLK2;
  RCC_ClkInitStruct.SYSCLKSource = RCC_SYSCLKSOURCE_PLLCLK;
  RCC_ClkInitStruct.AHBCLKDivider = RCC_SYSCLK_DIV1;
  RCC_ClkInitStruct.APB1CLKDivider = RCC_HCLK_DIV2;
  RCC_ClkInitStruct.APB2CLKDivider = RCC_HCLK_DIV1;

  if (HAL_RCC_ClockConfig(&RCC_ClkInitStruct, FLASH_LATENCY_3) != HAL_OK)
  {
    Error_Handler();
  }
}

static void MX_ADC1_Init(void)
{

  ADC_ChannelConfTypeDef sConfig = {0};

  /** Configure the global features of the ADC (Clock, Resolution, Data Alignment and number of conversion)
  */
  hadc1.Instance = ADC1;
  hadc1.Init.ClockPrescaler = ADC_CLOCK_SYNC_PCLK_DIV4;
  hadc1.Init.Resolution = ADC_RESOLUTION_12B;
  hadc1.Init.ScanConvMode = ADC_SCAN_DISABLE;
  hadc1.Init.ContinuousConvMode = DISABLE;
  hadc1.Init.DiscontinuousConvMode = DISABLE;
  hadc1.Init.ExternalTrigConvEdge = ADC_EXTERNALTRIGCONVEDGE_NONE;
  hadc1.Init.ExternalTrigConv = ADC_SOFTWARE_START;
  hadc1.Init.DataAlign = ADC_DATAALIGN_RIGHT;
  hadc1.Init.NbrOfConversion = 1;
  hadc1.Init.DMAContinuousRequests = DISABLE;
  hadc1.Init.EOCSelection = ADC_EOC_SINGLE_CONV;
  if (HAL_ADC_Init(&hadc1) != HAL_OK)
  {
    Error_Handler();
  }

  /** Configure for the selected ADC regular channel its corresponding rank in the sequencer and its sample time.
  */
  sConfig.Channel = ADC_CHANNEL_3;
  sConfig.Rank = ADC_REGULAR_RANK_1;
  sConfig.SamplingTime = ADC_SAMPLETIME_3CYCLES;
  if (HAL_ADC_ConfigChannel(&hadc1, &sConfig) != HAL_OK)
  {
    Error_Handler();
  }

}

static void MX_I2C1_Init(void)
{

  hi2c1.Instance = I2C1;
  hi2c1.Init.Timing = 0x20303E5D;
  hi2c1.Init.OwnAddress1 = 0;
  hi2c1.Init.AddressingMode = I2C_ADDRESSINGMODE_7BIT;
  hi2c1.Init.DualAddressMode = I2C_DUALADDRESS_DISABLE;
  hi2c1.Init.OwnAddress2 = 0;
  hi2c1.Init.OwnAddress2Masks = I2C_OA2_NOMASK;
  hi2c1.Init.GeneralCallMode = I2C_GENERALCALL_DISABLE;
  hi2c1.Init.NoStretchMode = I2C_NOSTRETCH_DISABLE;
  if (HAL_I2C_Init(&hi2c1) != HAL_OK)
  {
    Error_Handler();
  }

  /** Configure Analogue filter
  */
  if (HAL_I2CEx_ConfigAnalogFilter(&hi2c1, I2C_ANALOGFILTER_ENABLE) != HAL_OK)
  {
    Error_Handler();
  }

  /** Configure Digital filter
  */
  if (HAL_I2CEx_ConfigDigitalFilter(&hi2c1, 0) != HAL_OK)
  {
    Error_Handler();
  }

}

static void MX_I2C2_Init(void)
{

  hi2c2.Instance = I2C2;
  hi2c2.Init.Timing = 0x20303E5D;
  hi2c2.Init.OwnAddress1 = 0;
  hi2c2.Init.AddressingMode = I2C_ADDRESSINGMODE_7BIT;
  hi2c2.Init.DualAddressMode = I2C_DUALADDRESS_DISABLE;
  hi2c2.Init.OwnAddress2 = 0;
  hi2c2.Init.OwnAddress2Masks = I2C_OA2_NOMASK;
  hi2c2.Init.GeneralCallMode = I2C_GENERALCALL_DISABLE;
  hi2c2.Init.NoStretchMode = I2C_NOSTRETCH_DISABLE;
  if (HAL_I2C_Init(&hi2c2) != HAL_OK)
  {
    Error_Handler();
  }

  /** Configure Analogue filter
  */
  if (HAL_I2CEx_ConfigAnalogFilter(&hi2c2, I2C_ANALOGFILTER_ENABLE) != HAL_OK)
  {
    Error_Handler();
  }

  /** Configure Digital filter
  */
  if (HAL_I2CEx_ConfigDigitalFilter(&hi2c2, 0) != HAL_OK)
  {
    Error_Handler();
  }

}

static void MX_SPI1_Init(void)
{

  /* SPI1 parameter configuration*/
  hspi1.Instance = SPI1;
  hspi1.Init.Mode = SPI_MODE_MASTER;
  hspi1.Init.Direction = SPI_DIRECTION_2LINES;
  hspi1.Init.DataSize = SPI_DATASIZE_4BIT;
  hspi1.Init.CLKPolarity = SPI_POLARITY_LOW;
  hspi1.Init.CLKPhase = SPI_PHASE_1EDGE;
  hspi1.Init.NSS = SPI_NSS_SOFT;
  hspi1.Init.BaudRatePrescaler = SPI_BAUDRATEPRESCALER_2;
  hspi1.Init.FirstBit = SPI_FIRSTBIT_MSB;
  hspi1.Init.TIMode = SPI_TIMODE_DISABLE;
  hspi1.Init.CRCCalculation = SPI_CRCCALCULATION_DISABLE;
  hspi1.Init.CRCPolynomial = 7;
  hspi1.Init.CRCLength = SPI_CRC_LENGTH_DATASIZE;
  hspi1.Init.NSSPMode = SPI_NSS_PULSE_ENABLE;
  if (HAL_SPI_Init(&hspi1) != HAL_OK)
  {
    Error_Handler();
  }

}

static void MX_TIM1_Init(void)
{

  TIM_ClockConfigTypeDef sClockSourceConfig = {0};
  TIM_MasterConfigTypeDef sMasterConfig = {0};
  TIM_OC_InitTypeDef sConfigOC = {0};
  TIM_BreakDeadTimeConfigTypeDef sBreakDeadTimeConfig = {0};

  htim1.Instance = TIM1;
  htim1.Init.Prescaler = 0;
  htim1.Init.CounterMode = TIM_COUNTERMODE_UP;
  htim1.Init.Period = 0;
  htim1.Init.ClockDivision = TIM_CLOCKDIVISION_DIV1;
  htim1.Init.RepetitionCounter = 0;
  htim1.Init.AutoReloadPreload = TIM_AUTORELOAD_PRELOAD_DISABLE;
  if (HAL_TIM_Base_Init(&htim1) != HAL_OK)
  {
    Error_Handler();
  }
  sClockSourceConfig.ClockSource = TIM_CLOCKSOURCE_INTERNAL;
  if (HAL_TIM_ConfigClockSource(&htim1, &sClockSourceConfig) != HAL_OK)
  {
    Error_Handler();
  }
  if (HAL_TIM_OC_Init(&htim1) != HAL_OK)
  {
    Error_Handler();
  }
  sMasterConfig.MasterOutputTrigger = TIM_TRGO_RESET;
  sMasterConfig.MasterOutputTrigger2 = TIM_TRGO2_RESET;
  sMasterConfig.MasterSlaveMode = TIM_MASTERSLAVEMODE_DISABLE;
  if (HAL_TIMEx_MasterConfigSynchronization(&htim1, &sMasterConfig) != HAL_OK)
  {
    Error_Handler();
  }
  sConfigOC.OCMode = TIM_OCMODE_FORCED_ACTIVE;
  sConfigOC.Pulse = 0;
  sConfigOC.OCPolarity = TIM_OCPOLARITY_LOW;
  sConfigOC.OCNPolarity = TIM_OCNPOLARITY_HIGH;
  sConfigOC.OCFastMode = TIM_OCFAST_DISABLE;
  sConfigOC.OCIdleState = TIM_OCIDLESTATE_RESET;
  sConfigOC.OCNIdleState = TIM_OCNIDLESTATE_RESET;
  if (HAL_TIM_OC_ConfigChannel(&htim1, &sConfigOC, TIM_CHANNEL_1) != HAL_OK)
  {
    Error_Handler();
  }
  if (HAL_TIM_OC_ConfigChannel(&htim1, &sConfigOC, TIM_CHANNEL_2) != HAL_OK)
  {
    Error_Handler();
  }
  if (HAL_TIM_OC_ConfigChannel(&htim1, &sConfigOC, TIM_CHANNEL_3) != HAL_OK)
  {
    Error_Handler();
  }
  if (HAL_TIM_OC_ConfigChannel(&htim1, &sConfigOC, TIM_CHANNEL_4) != HAL_OK)
  {
    Error_Handler();
  }
  sBreakDeadTimeConfig.OffStateRunMode = TIM_OSSR_DISABLE;
  sBreakDeadTimeConfig.OffStateIDLEMode = TIM_OSSI_DISABLE;
  sBreakDeadTimeConfig.LockLevel = TIM_LOCKLEVEL_OFF;
  sBreakDeadTimeConfig.DeadTime = 0;
  sBreakDeadTimeConfig.BreakState = TIM_BREAK_DISABLE;
  sBreakDeadTimeConfig.BreakPolarity = TIM_BREAKPOLARITY_HIGH;
  sBreakDeadTimeConfig.BreakFilter = 0;
  sBreakDeadTimeConfig.Break2State = TIM_BREAK2_DISABLE;
  sBreakDeadTimeConfig.Break2Polarity = TIM_BREAK2POLARITY_HIGH;
  sBreakDeadTimeConfig.Break2Filter = 0;
  sBreakDeadTimeConfig.AutomaticOutput = TIM_AUTOMATICOUTPUT_DISABLE;
  if (HAL_TIMEx_ConfigBreakDeadTime(&htim1, &sBreakDeadTimeConfig) != HAL_OK)
  {
    Error_Handler();
  }
  HAL_TIM_MspPostInit(&htim1);

}

static void MX_TIM2_Init(void)
{

  TIM_ClockConfigTypeDef sClockSourceConfig = {0};
  TIM_MasterConfigTypeDef sMasterConfig = {0};
  TIM_OC_InitTypeDef sConfigOC = {0};
  TIM_IC_InitTypeDef sConfigIC = {0};

  htim2.Instance = TIM2;
  htim2.Init.Prescaler = 0;
  htim2.Init.CounterMode = TIM_COUNTERMODE_UP;
  htim2.Init.Period = 4294967295;
  htim2.Init.ClockDivision = TIM_CLOCKDIVISION_DIV1;
  htim2.Init.AutoReloadPreload = TIM_AUTORELOAD_PRELOAD_DISABLE;
  if (HAL_TIM_Base_Init(&htim2) != HAL_OK)
  {
    Error_Handler();
  }
  sClockSourceConfig.ClockSource = TIM_CLOCKSOURCE_INTERNAL;
  if (HAL_TIM_ConfigClockSource(&htim2, &sClockSourceConfig) != HAL_OK)
  {
    Error_Handler();
  }
  if (HAL_TIM_PWM_Init(&htim2) != HAL_OK)
  {
    Error_Handler();
  }
  if (HAL_TIM_IC_Init(&htim2) != HAL_OK)
  {
    Error_Handler();
  }
  sMasterConfig.MasterOutputTrigger = TIM_TRGO_RESET;
  sMasterConfig.MasterSlaveMode = TIM_MASTERSLAVEMODE_DISABLE;
  if (HAL_TIMEx_MasterConfigSynchronization(&htim2, &sMasterConfig) != HAL_OK)
  {
    Error_Handler();
  }
  sConfigOC.OCMode = TIM_OCMODE_PWM1;
  sConfigOC.Pulse = 0;
  sConfigOC.OCPolarity = TIM_OCPOLARITY_HIGH;
  sConfigOC.OCFastMode = TIM_OCFAST_DISABLE;
  if (HAL_TIM_PWM_ConfigChannel(&htim2, &sConfigOC, TIM_CHANNEL_1) != HAL_OK)
  {
    Error_Handler();
  }
  sConfigIC.ICPolarity = TIM_INPUTCHANNELPOLARITY_RISING;
  sConfigIC.ICSelection = TIM_ICSELECTION_DIRECTTI;
  sConfigIC.ICPrescaler = TIM_ICPSC_DIV1;
  sConfigIC.ICFilter = 0;
  if (HAL_TIM_IC_ConfigChannel(&htim2, &sConfigIC, TIM_CHANNEL_3) != HAL_OK)
  {
    Error_Handler();
  }
  HAL_TIM_MspPostInit(&htim2);

}

static void MX_TIM3_Init(void)
{

  TIM_Encoder_InitTypeDef sConfig = {0};
  TIM_MasterConfigTypeDef sMasterConfig = {0};

  htim3.Instance = TIM3;
  htim3.Init.Prescaler = 0;
  htim3.Init.CounterMode = TIM_COUNTERMODE_UP;
  htim3.Init.Period = TIM3_ARR_VALUE;
  htim3.Init.ClockDivision = TIM_CLOCKDIVISION_DIV1;
  htim3.Init.AutoReloadPreload = TIM_AUTORELOAD_PRELOAD_DISABLE;
  sConfig.EncoderMode = TIM_ENCODERMODE_TI12;
  sConfig.IC1Polarity = TIM_ICPOLARITY_RISING;
  sConfig.IC1Selection = TIM_ICSELECTION_DIRECTTI;
  sConfig.IC1Prescaler = TIM_ICPSC_DIV1;
  sConfig.IC1Filter = 15;
  sConfig.IC2Polarity = TIM_ICPOLARITY_RISING;
  sConfig.IC2Selection = TIM_ICSELECTION_DIRECTTI;
  sConfig.IC2Prescaler = TIM_ICPSC_DIV1;
  sConfig.IC2Filter = 15;
  if (HAL_TIM_Encoder_Init(&htim3, &sConfig) != HAL_OK)
  {
    Error_Handler();
  }
  sMasterConfig.MasterOutputTrigger = TIM_TRGO_RESET;
  sMasterConfig.MasterSlaveMode = TIM_MASTERSLAVEMODE_DISABLE;
  if (HAL_TIMEx_MasterConfigSynchronization(&htim3, &sMasterConfig) != HAL_OK)
  {
    Error_Handler();
  }

}

static void MX_TIM4_Init(void)
{

  TIM_Encoder_InitTypeDef sConfig = {0};
  TIM_MasterConfigTypeDef sMasterConfig = {0};

  htim4.Instance = TIM4;
  htim4.Init.Prescaler = 0;
  htim4.Init.CounterMode = TIM_COUNTERMODE_UP;
  htim4.Init.Period = TIM4_ARR_VALUE;
  htim4.Init.ClockDivision = TIM_CLOCKDIVISION_DIV1;
  htim4.Init.AutoReloadPreload = TIM_AUTORELOAD_PRELOAD_DISABLE;
  sConfig.EncoderMode = TIM_ENCODERMODE_TI12;
  sConfig.IC1Polarity = TIM_ICPOLARITY_RISING;
  sConfig.IC1Selection = TIM_ICSELECTION_DIRECTTI;
  sConfig.IC1Prescaler = TIM_ICPSC_DIV1;
  sConfig.IC1Filter = 15;
  sConfig.IC2Polarity = TIM_ICPOLARITY_RISING;
  sConfig.IC2Selection = TIM_ICSELECTION_DIRECTTI;
  sConfig.IC2Prescaler = TIM_ICPSC_DIV1;
  sConfig.IC2Filter = 15;
  if (HAL_TIM_Encoder_Init(&htim4, &sConfig) != HAL_OK)
  {
    Error_Handler();
  }
  sMasterConfig.MasterOutputTrigger = TIM_TRGO_RESET;
  sMasterConfig.MasterSlaveMode = TIM_MASTERSLAVEMODE_DISABLE;
  if (HAL_TIMEx_MasterConfigSynchronization(&htim4, &sMasterConfig) != HAL_OK)
  {
    Error_Handler();
  }

}

static void MX_TIM5_Init(void)
{

  TIM_ClockConfigTypeDef sClockSourceConfig = {0};
  TIM_MasterConfigTypeDef sMasterConfig = {0};
  TIM_OC_InitTypeDef sConfigOC = {0};

  htim5.Instance = TIM5;
  htim5.Init.Prescaler = 0;
  htim5.Init.CounterMode = TIM_COUNTERMODE_UP;
  htim5.Init.Period = 4294967295;
  htim5.Init.ClockDivision = TIM_CLOCKDIVISION_DIV1;
  htim5.Init.AutoReloadPreload = TIM_AUTORELOAD_PRELOAD_DISABLE;
  if (HAL_TIM_Base_Init(&htim5) != HAL_OK)
  {
    Error_Handler();
  }
  sClockSourceConfig.ClockSource = TIM_CLOCKSOURCE_INTERNAL;
  if (HAL_TIM_ConfigClockSource(&htim5, &sClockSourceConfig) != HAL_OK)
  {
    Error_Handler();
  }
  if (HAL_TIM_PWM_Init(&htim5) != HAL_OK)
  {
    Error_Handler();
  }
  sMasterConfig.MasterOutputTrigger = TIM_TRGO_RESET;
  sMasterConfig.MasterSlaveMode = TIM_MASTERSLAVEMODE_DISABLE;
  if (HAL_TIMEx_MasterConfigSynchronization(&htim5, &sMasterConfig) != HAL_OK)
  {
    Error_Handler();
  }
  sConfigOC.OCMode = TIM_OCMODE_PWM1;
  sConfigOC.Pulse = 0;
  sConfigOC.OCPolarity = TIM_OCPOLARITY_HIGH;
  sConfigOC.OCFastMode = TIM_OCFAST_DISABLE;
  if (HAL_TIM_PWM_ConfigChannel(&htim5, &sConfigOC, TIM_CHANNEL_1) != HAL_OK)
  {
    Error_Handler();
  }
  HAL_TIM_MspPostInit(&htim5);

}

static void MX_TIM6_Init(void)
{

  TIM_MasterConfigTypeDef sMasterConfig = {0};

  htim6.Instance = TIM6;
  htim6.Init.Prescaler = TIM6_PSC_VALUE;
  htim6.Init.CounterMode = TIM_COUNTERMODE_UP;
  htim6.Init.Period = TIM6_ARR_VALUE;
  htim6.Init.AutoReloadPreload = TIM_AUTORELOAD_PRELOAD_DISABLE;
  if (HAL_TIM_Base_Init(&htim6) != HAL_OK)
  {
    Error_Handler();
  }
  sMasterConfig.MasterOutputTrigger = TIM_TRGO_RESET;
  sMasterConfig.MasterSlaveMode = TIM_MASTERSLAVEMODE_DISABLE;
  if (HAL_TIMEx_MasterConfigSynchronization(&htim6, &sMasterConfig) != HAL_OK)
  {
    Error_Handler();
  }

}

static void MX_TIM8_Init(void)
{

  TIM_ClockConfigTypeDef sClockSourceConfig = {0};
  TIM_MasterConfigTypeDef sMasterConfig = {0};
  TIM_OC_InitTypeDef sConfigOC = {0};
  TIM_BreakDeadTimeConfigTypeDef sBreakDeadTimeConfig = {0};

  htim8.Instance = TIM8;
  htim8.Init.Prescaler = TIM8_PSC_VALUE;
  htim8.Init.CounterMode = TIM_COUNTERMODE_UP;
  htim8.Init.Period = TIM8_ARR_VALUE;
  htim8.Init.ClockDivision = TIM_CLOCKDIVISION_DIV1;
  htim8.Init.RepetitionCounter = 0;
  htim8.Init.AutoReloadPreload = TIM_AUTORELOAD_PRELOAD_DISABLE;
  if (HAL_TIM_Base_Init(&htim8) != HAL_OK)
  {
    Error_Handler();
  }
  sClockSourceConfig.ClockSource = TIM_CLOCKSOURCE_INTERNAL;
  if (HAL_TIM_ConfigClockSource(&htim8, &sClockSourceConfig) != HAL_OK)
  {
    Error_Handler();
  }
  if (HAL_TIM_PWM_Init(&htim8) != HAL_OK)
  {
    Error_Handler();
  }
  sMasterConfig.MasterOutputTrigger = TIM_TRGO_RESET;
  sMasterConfig.MasterOutputTrigger2 = TIM_TRGO2_RESET;
  sMasterConfig.MasterSlaveMode = TIM_MASTERSLAVEMODE_DISABLE;
  if (HAL_TIMEx_MasterConfigSynchronization(&htim8, &sMasterConfig) != HAL_OK)
  {
    Error_Handler();
  }
  sConfigOC.OCMode = TIM_OCMODE_PWM1;
  sConfigOC.Pulse = 0;
  sConfigOC.OCPolarity = TIM_OCPOLARITY_HIGH;
  sConfigOC.OCNPolarity = TIM_OCNPOLARITY_HIGH;
  sConfigOC.OCFastMode = TIM_OCFAST_DISABLE;
  sConfigOC.OCIdleState = TIM_OCIDLESTATE_RESET;
  sConfigOC.OCNIdleState = TIM_OCNIDLESTATE_RESET;
  if (HAL_TIM_PWM_ConfigChannel(&htim8, &sConfigOC, TIM_CHANNEL_1) != HAL_OK)
  {
    Error_Handler();
  }
  if (HAL_TIM_PWM_ConfigChannel(&htim8, &sConfigOC, TIM_CHANNEL_2) != HAL_OK)
  {
    Error_Handler();
  }
  if (HAL_TIM_PWM_ConfigChannel(&htim8, &sConfigOC, TIM_CHANNEL_3) != HAL_OK)
  {
    Error_Handler();
  }
  if (HAL_TIM_PWM_ConfigChannel(&htim8, &sConfigOC, TIM_CHANNEL_4) != HAL_OK)
  {
    Error_Handler();
  }
  sBreakDeadTimeConfig.OffStateRunMode = TIM_OSSR_DISABLE;
  sBreakDeadTimeConfig.OffStateIDLEMode = TIM_OSSI_DISABLE;
  sBreakDeadTimeConfig.LockLevel = TIM_LOCKLEVEL_OFF;
  sBreakDeadTimeConfig.DeadTime = 0;
  sBreakDeadTimeConfig.BreakState = TIM_BREAK_DISABLE;
  sBreakDeadTimeConfig.BreakPolarity = TIM_BREAKPOLARITY_HIGH;
  sBreakDeadTimeConfig.BreakFilter = 0;
  sBreakDeadTimeConfig.Break2State = TIM_BREAK2_DISABLE;
  sBreakDeadTimeConfig.Break2Polarity = TIM_BREAK2POLARITY_HIGH;
  sBreakDeadTimeConfig.Break2Filter = 0;
  sBreakDeadTimeConfig.AutomaticOutput = TIM_AUTOMATICOUTPUT_DISABLE;
  if (HAL_TIMEx_ConfigBreakDeadTime(&htim8, &sBreakDeadTimeConfig) != HAL_OK)
  {
    Error_Handler();
  }
  HAL_TIM_MspPostInit(&htim8);

}

static void MX_TIM9_Init(void)
{

  TIM_OC_InitTypeDef sConfigOC = {0};

  htim9.Instance = TIM9;
  htim9.Init.Prescaler = 0;
  htim9.Init.CounterMode = TIM_COUNTERMODE_UP;
  htim9.Init.Period = 65535;
  htim9.Init.ClockDivision = TIM_CLOCKDIVISION_DIV1;
  htim9.Init.AutoReloadPreload = TIM_AUTORELOAD_PRELOAD_DISABLE;
  if (HAL_TIM_PWM_Init(&htim9) != HAL_OK)
  {
    Error_Handler();
  }
  sConfigOC.OCMode = TIM_OCMODE_PWM1;
  sConfigOC.Pulse = 0;
  sConfigOC.OCPolarity = TIM_OCPOLARITY_HIGH;
  sConfigOC.OCFastMode = TIM_OCFAST_DISABLE;
  if (HAL_TIM_PWM_ConfigChannel(&htim9, &sConfigOC, TIM_CHANNEL_1) != HAL_OK)
  {
    Error_Handler();
  }
  if (HAL_TIM_PWM_ConfigChannel(&htim9, &sConfigOC, TIM_CHANNEL_2) != HAL_OK)
  {
    Error_Handler();
  }
  HAL_TIM_MspPostInit(&htim9);

}

static void MX_UART4_Init(void)
{

  huart4.Instance = UART4;
  huart4.Init.BaudRate = 9600;
  huart4.Init.WordLength = UART_WORDLENGTH_8B;
  huart4.Init.StopBits = UART_STOPBITS_1;
  huart4.Init.Parity = UART_PARITY_NONE;
  huart4.Init.Mode = UART_MODE_TX_RX;
  huart4.Init.HwFlowCtl = UART_HWCONTROL_NONE;
  huart4.Init.OverSampling = UART_OVERSAMPLING_16;
  huart4.Init.OneBitSampling = UART_ONE_BIT_SAMPLE_DISABLE;
  huart4.AdvancedInit.AdvFeatureInit = UART_ADVFEATURE_NO_INIT;
  if (HAL_UART_Init(&huart4) != HAL_OK)
  {
    Error_Handler();
  }

}

static void MX_UART5_Init(void)
{

  huart5.Instance = UART5;
  huart5.Init.BaudRate = 115200;
  huart5.Init.WordLength = UART_WORDLENGTH_8B;
  huart5.Init.StopBits = UART_STOPBITS_1;
  huart5.Init.Parity = UART_PARITY_NONE;
  huart5.Init.Mode = UART_MODE_TX_RX;
  huart5.Init.HwFlowCtl = UART_HWCONTROL_NONE;
  huart5.Init.OverSampling = UART_OVERSAMPLING_16;
  huart5.Init.OneBitSampling = UART_ONE_BIT_SAMPLE_DISABLE;
  huart5.AdvancedInit.AdvFeatureInit = UART_ADVFEATURE_NO_INIT;
  if (HAL_UART_Init(&huart5) != HAL_OK)
  {
    Error_Handler();
  }

}

static void MX_USART1_UART_Init(void)
{

  huart1.Instance = USART1;
  huart1.Init.BaudRate = 115200;
  huart1.Init.WordLength = UART_WORDLENGTH_8B;
  huart1.Init.StopBits = UART_STOPBITS_1;
  huart1.Init.Parity = UART_PARITY_NONE;
  huart1.Init.Mode = UART_MODE_TX_RX;
  huart1.Init.HwFlowCtl = UART_HWCONTROL_NONE;
  huart1.Init.OverSampling = UART_OVERSAMPLING_16;
  huart1.Init.OneBitSampling = UART_ONE_BIT_SAMPLE_DISABLE;
  huart1.AdvancedInit.AdvFeatureInit = UART_ADVFEATURE_NO_INIT;
  if (HAL_UART_Init(&huart1) != HAL_OK)
  {
    Error_Handler();
  }

}

static void MX_USART2_UART_Init(void)
{

  huart2.Instance = USART2;
  huart2.Init.BaudRate = 1000000;
  huart2.Init.WordLength = UART_WORDLENGTH_8B;
  huart2.Init.StopBits = UART_STOPBITS_1;
  huart2.Init.Parity = UART_PARITY_NONE;
  huart2.Init.Mode = UART_MODE_TX_RX;
  huart2.Init.HwFlowCtl = UART_HWCONTROL_NONE;
  huart2.Init.OverSampling = UART_OVERSAMPLING_16;
  huart2.Init.OneBitSampling = UART_ONE_BIT_SAMPLE_DISABLE;
  huart2.AdvancedInit.AdvFeatureInit = UART_ADVFEATURE_NO_INIT;
  if (HAL_UART_Init(&huart2) != HAL_OK)
  {
    Error_Handler();
  }

}

static void MX_USART3_UART_Init(void)
{

  huart3.Instance = USART3;
  huart3.Init.BaudRate = 115200;
  huart3.Init.WordLength = UART_WORDLENGTH_8B;
  huart3.Init.StopBits = UART_STOPBITS_1;
  huart3.Init.Parity = UART_PARITY_NONE;
  huart3.Init.Mode = UART_MODE_TX_RX;
  huart3.Init.HwFlowCtl = UART_HWCONTROL_NONE;
  huart3.Init.OverSampling = UART_OVERSAMPLING_16;
  huart3.Init.OneBitSampling = UART_ONE_BIT_SAMPLE_DISABLE;
  huart3.AdvancedInit.AdvFeatureInit = UART_ADVFEATURE_NO_INIT;
  if (HAL_UART_Init(&huart3) != HAL_OK)
  {
    Error_Handler();
  }

}

static void MX_GPIO_Init(void)
{
  GPIO_InitTypeDef GPIO_InitStruct = {0};

  /* GPIO Ports Clock Enable */
  __HAL_RCC_GPIOE_CLK_ENABLE();
  __HAL_RCC_GPIOC_CLK_ENABLE();
  __HAL_RCC_GPIOF_CLK_ENABLE();
  __HAL_RCC_GPIOH_CLK_ENABLE();
  __HAL_RCC_GPIOA_CLK_ENABLE();
  __HAL_RCC_GPIOB_CLK_ENABLE();
  __HAL_RCC_GPIOD_CLK_ENABLE();
  __HAL_RCC_GPIOG_CLK_ENABLE();

  /*Configure GPIO pin Output Level */
  HAL_GPIO_WritePin(GPIOE, GPIO_OUT_SPI_CS_SDCARD_Pin|GPIO_OUT_SPI_CS_LCD_Pin, GPIO_PIN_RESET);

  /*Configure GPIO pin Output Level */
  HAL_GPIO_WritePin(GPIOB, LD1_Pin|LD3_Pin|LD2_Pin, GPIO_PIN_RESET);

  /*Configure GPIO pin Output Level */
  HAL_GPIO_WritePin(GPIOG, GPIO_PIN_6, GPIO_PIN_RESET);

  /*Configure GPIO pins : GPIO_OUT_SPI_CS_SDCARD_Pin GPIO_OUT_SPI_CS_LCD_Pin */
  GPIO_InitStruct.Pin = GPIO_OUT_SPI_CS_SDCARD_Pin|GPIO_OUT_SPI_CS_LCD_Pin;
  GPIO_InitStruct.Mode = GPIO_MODE_OUTPUT_PP;
  GPIO_InitStruct.Pull = GPIO_NOPULL;
  GPIO_InitStruct.Speed = GPIO_SPEED_FREQ_LOW;
  HAL_GPIO_Init(GPIOE, &GPIO_InitStruct);

  /*Configure GPIO pins : GPIO_EXTI2_PROXY_TOF_SENS_IRQ_Pin GPIO_EXTI3_IMU_IRQ_Pin GPIO_EXTI4_KPAD_IRQ_Pin GPIO_EXTI8_USER_BUT1_IRQ_Pin
                           GPIO_EXTI9_USER_BUT2_IRQ_Pin GPIO_EXTI10_BUMP1_IRQ_Pin GPIO_EXTI11_BUMP2_IRQ_Pin GPIO_EXTI12_BUMP3_IRQ_Pin
                           GPIO_EXTI13_BUMP4_IRQ_Pin */
  GPIO_InitStruct.Pin = GPIO_EXTI2_PROXY_TOF_SENS_IRQ_Pin|GPIO_EXTI3_IMU_IRQ_Pin|GPIO_EXTI4_KPAD_IRQ_Pin|GPIO_EXTI8_USER_BUT1_IRQ_Pin
                          |GPIO_EXTI9_USER_BUT2_IRQ_Pin|GPIO_EXTI10_BUMP1_IRQ_Pin|GPIO_EXTI11_BUMP2_IRQ_Pin|GPIO_EXTI12_BUMP3_IRQ_Pin
                          |GPIO_EXTI13_BUMP4_IRQ_Pin;
  GPIO_InitStruct.Mode = GPIO_MODE_IT_RISING;
  GPIO_InitStruct.Pull = GPIO_NOPULL;
  HAL_GPIO_Init(GPIOF, &GPIO_InitStruct);

  /*Configure GPIO pins : RMII_MDC_Pin RMII_RXD0_Pin RMII_RXD1_Pin */
  GPIO_InitStruct.Pin = RMII_MDC_Pin|RMII_RXD0_Pin|RMII_RXD1_Pin;
  GPIO_InitStruct.Mode = GPIO_MODE_AF_PP;
  GPIO_InitStruct.Pull = GPIO_NOPULL;
  GPIO_InitStruct.Speed = GPIO_SPEED_FREQ_VERY_HIGH;
  GPIO_InitStruct.Alternate = GPIO_AF11_ETH;
  HAL_GPIO_Init(GPIOC, &GPIO_InitStruct);

  /*Configure GPIO pins : RMII_REF_CLK_Pin RMII_MDIO_Pin RMII_CRS_DV_Pin */
  GPIO_InitStruct.Pin = RMII_REF_CLK_Pin|RMII_MDIO_Pin|RMII_CRS_DV_Pin;
  GPIO_InitStruct.Mode = GPIO_MODE_AF_PP;
  GPIO_InitStruct.Pull = GPIO_NOPULL;
  GPIO_InitStruct.Speed = GPIO_SPEED_FREQ_VERY_HIGH;
  GPIO_InitStruct.Alternate = GPIO_AF11_ETH;
  HAL_GPIO_Init(GPIOA, &GPIO_InitStruct);

  /*Configure GPIO pins : LD1_Pin LD3_Pin LD2_Pin */
  GPIO_InitStruct.Pin = LD1_Pin|LD3_Pin|LD2_Pin;
  GPIO_InitStruct.Mode = GPIO_MODE_OUTPUT_PP;
  GPIO_InitStruct.Pull = GPIO_NOPULL;
  GPIO_InitStruct.Speed = GPIO_SPEED_FREQ_LOW;
  HAL_GPIO_Init(GPIOB, &GPIO_InitStruct);

  /*Configure GPIO pin : RMII_TXD1_Pin */
  GPIO_InitStruct.Pin = RMII_TXD1_Pin;
  GPIO_InitStruct.Mode = GPIO_MODE_AF_PP;
  GPIO_InitStruct.Pull = GPIO_NOPULL;
  GPIO_InitStruct.Speed = GPIO_SPEED_FREQ_VERY_HIGH;
  GPIO_InitStruct.Alternate = GPIO_AF11_ETH;
  HAL_GPIO_Init(RMII_TXD1_GPIO_Port, &GPIO_InitStruct);

  /*Configure GPIO pin : PG6 */
  GPIO_InitStruct.Pin = GPIO_PIN_6;
  GPIO_InitStruct.Mode = GPIO_MODE_OUTPUT_PP;
  GPIO_InitStruct.Pull = GPIO_NOPULL;
  GPIO_InitStruct.Speed = GPIO_SPEED_FREQ_LOW;
  HAL_GPIO_Init(GPIOG, &GPIO_InitStruct);

  /*Configure GPIO pin : USB_OverCurrent_Pin */
  GPIO_InitStruct.Pin = USB_OverCurrent_Pin;
  GPIO_InitStruct.Mode = GPIO_MODE_INPUT;
  GPIO_InitStruct.Pull = GPIO_NOPULL;
  HAL_GPIO_Init(USB_OverCurrent_GPIO_Port, &GPIO_InitStruct);

  /*Configure GPIO pins : USB_SOF_Pin USB_ID_Pin USB_DM_Pin USB_DP_Pin */
  GPIO_InitStruct.Pin = USB_SOF_Pin|USB_ID_Pin|USB_DM_Pin|USB_DP_Pin;
  GPIO_InitStruct.Mode = GPIO_MODE_AF_PP;
  GPIO_InitStruct.Pull = GPIO_NOPULL;
  GPIO_InitStruct.Speed = GPIO_SPEED_FREQ_VERY_HIGH;
  GPIO_InitStruct.Alternate = GPIO_AF10_OTG_FS;
  HAL_GPIO_Init(GPIOA, &GPIO_InitStruct);

  /*Configure GPIO pin : USB_VBUS_Pin */
  GPIO_InitStruct.Pin = USB_VBUS_Pin;
  GPIO_InitStruct.Mode = GPIO_MODE_INPUT;
  GPIO_InitStruct.Pull = GPIO_NOPULL;
  HAL_GPIO_Init(USB_VBUS_GPIO_Port, &GPIO_InitStruct);

  /*Configure GPIO pins : RMII_TX_EN_Pin RMII_TXD0_Pin */
  GPIO_InitStruct.Pin = RMII_TX_EN_Pin|RMII_TXD0_Pin;
  GPIO_InitStruct.Mode = GPIO_MODE_AF_PP;
  GPIO_InitStruct.Pull = GPIO_NOPULL;
  GPIO_InitStruct.Speed = GPIO_SPEED_FREQ_VERY_HIGH;
  GPIO_InitStruct.Alternate = GPIO_AF11_ETH;
  HAL_GPIO_Init(GPIOG, &GPIO_InitStruct);

}

void Error_Handler(void)
{
  __disable_irq();
  while (1)
  {
  }
}
